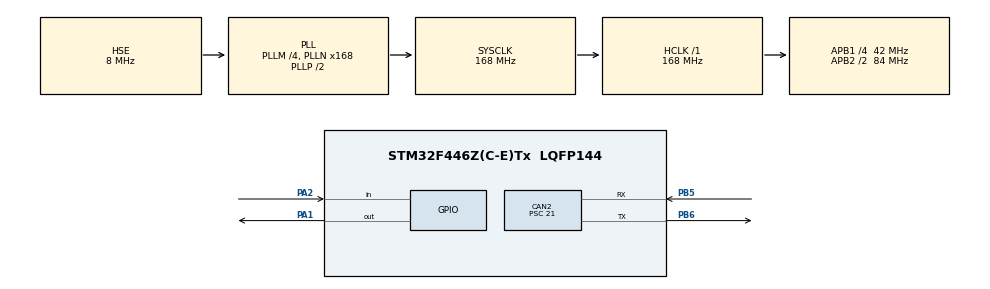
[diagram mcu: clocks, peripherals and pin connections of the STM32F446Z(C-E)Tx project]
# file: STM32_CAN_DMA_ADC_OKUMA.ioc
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CAN2.BS1=CAN_BS1_2TQ
CAN2.CalculateBaudRate=500000
CAN2.CalculateTimeBit=2000
CAN2.CalculateTimeQuantum=500.0
CAN2.Prescaler=21
Mcu.Family=STM32F4
Mcu.Name=STM32F446Z(C-E)Tx
Mcu.Package=LQFP144
NVIC.CAN2_RX0_IRQn=true\:0\:0\:false\:false\:true\:true\:true\:true
NVIC.PriorityGroup=NVIC_PRIORITYGROUP_4
PA1.Signal=GPIO_Output
PA2.Signal=GPIO_Input
PB5.Mode=CAN_Activate
PB5.Signal=CAN2_RX
PB6.Mode=CAN_Activate
PB6.Signal=CAN2_TX
PH0-OSC_IN.Mode=HSE-External-Oscillator
PH0-OSC_IN.Signal=RCC_OSC_IN
PH1-OSC_OUT.Mode=HSE-External-Oscillator
PH1-OSC_OUT.Signal=RCC_OSC_OUT
ProjectManager.HeapSize=0x200
ProjectManager.StackSize=0x400
ProjectManager.TargetToolchain=STM32CubeIDE
RCC.AHBFreq_Value=168000000
RCC.APB1CLKDivider=RCC_HCLK_DIV4
RCC.APB1Freq_Value=42000000
RCC.APB1TimFreq_Value=84000000
RCC.APB2CLKDivider=RCC_HCLK_DIV2
RCC.APB2Freq_Value=84000000
RCC.APB2TimFreq_Value=168000000
RCC.CortexFreq_Value=168000000
RCC.HCLKFreq_Value=168000000
RCC.HSE_VALUE=8000000
RCC.PLLM=4
RCC.PLLN=168
RCC.PLLSourceVirtual=RCC_PLLSOURCE_HSE
RCC.SYSCLKFreq_VALUE=168000000
RCC.SYSCLKSource=RCC_SYSCLKSOURCE_PLLCLK
RCC.USBFreq_Value=168000000
RCC.VCOOutputFreq_Value=336000000
board=custom

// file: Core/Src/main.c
/* USER CODE BEGIN Header */
/**
  ******************************************************************************
  * @file           : main.c
  * @brief          : Main program body
  ******************************************************************************
  * @attention
  *
  * Copyright (c) 2024 STMicroelectronics.
  * All rights reserved.
  *
  * This software is licensed under terms that can be found in the LICENSE file
  * in the root directory of this software component.
  * If no LICENSE file comes with this software, it is provided AS-IS.
  *
  ******************************************************************************
  */
/* USER CODE END Header */
#include "main.h"

CAN_HandleTypeDef hcan2;

/* USER CODE BEGIN PV */
uint8_t adc_value;

/* USER CODE END PV */

void SystemClock_Config(void);
static void MX_GPIO_Init(void);
static void MX_CAN2_Init(void);

int main(void)
{

  /* MCU Configuration--------------------------------------------------------*/

  /* Reset of all peripherals, Initializes the Flash interface and the Systick. */
  HAL_Init();

  /* Configure the system clock */
  SystemClock_Config();

  /* Initialize all configured peripherals */
  MX_GPIO_Init();
  MX_CAN2_Init();
  /* USER CODE BEGIN 2 */

  HAL_CAN_Start(&hcan2);
  HAL_ADC_Start_DMA(&hadc1, &adc_value, 1);

  /* USER CODE END 2 */

  /* Infinite loop */
  while (1)
  {

  }
}

void SystemClock_Config(void)
{
  RCC_OscInitTypeDef RCC_OscInitStruct = {0};
  RCC_ClkInitTypeDef RCC_ClkInitStruct = {0};

  /** Configure the main internal regulator output voltage
  */
  __HAL_RCC_PWR_CLK_ENABLE();
  __HAL_PWR_VOLTAGESCALING_CONFIG(PWR_REGULATOR_VOLTAGE_SCALE1);

  /** Initializes the RCC Oscillators according to the specified parameters
  * in the RCC_OscInitTypeDef structure.
  */
  RCC_OscInitStruct.OscillatorType = RCC_OSCILLATORTYPE_HSE;
  RCC_OscInitStruct.HSEState = RCC_HSE_ON;
  RCC_OscInitStruct.PLL.PLLState = RCC_PLL_ON;
  RCC_OscInitStruct.PLL.PLLSource = RCC_PLLSOURCE_HSE;
  RCC_OscInitStruct.PLL.PLLM = 4;
  RCC_OscInitStruct.PLL.PLLN = 168;
  RCC_OscInitStruct.PLL.PLLP = RCC_PLLP_DIV2;
  RCC_OscInitStruct.PLL.PLLQ = 2;
  RCC_OscInitStruct.PLL.PLLR = 2;
  if (HAL_RCC_OscConfig(&RCC_OscInitStruct) != HAL_OK)
  {
    Error_Handler();
  }

  /** Initializes the CPU, AHB and APB buses clocks
  */
  RCC_ClkInitStruct.ClockType = RCC_CLOCKTYPE_HCLK|RCC_CLOCKTYPE_SYSCLK
                              |RCC_CLOCKTYPE_PCLK1|RCC_CLOCKTYPE_PCLK2;
  RCC_ClkInitStruct.SYSCLKSource = RCC_SYSCLKSOURCE_PLLCLK;
  RCC_ClkInitStruct.AHBCLKDivider = RCC_SYSCLK_DIV1;
  RCC_ClkInitStruct.APB1CLKDivider = RCC_HCLK_DIV4;
  RCC_ClkInitStruct.APB2CLKDivider = RCC_HCLK_DIV2;

  if (HAL_RCC_ClockConfig(&RCC_ClkInitStruct, FLASH_LATENCY_5) != HAL_OK)
  {
    Error_Handler();
  }
}

static void MX_CAN2_Init(void)
{

  hcan2.Instance = CAN2;
  hcan2.Init.Prescaler = 21;
  hcan2.Init.Mode = CAN_MODE_NORMAL;
  hcan2.Init.SyncJumpWidth = CAN_SJW_1TQ;
  hcan2.Init.TimeSeg1 = CAN_BS1_2TQ;
  hcan2.Init.TimeSeg2 = CAN_BS2_1TQ;
  hcan2.Init.TimeTriggeredMode = DISABLE;
  hcan2.Init.AutoBusOff = DISABLE;
  hcan2.Init.AutoWakeUp = DISABLE;
  hcan2.Init.AutoRetransmission = DISABLE;
  hcan2.Init.ReceiveFifoLocked = DISABLE;
  hcan2.Init.TransmitFifoPriority = DISABLE;
  if (HAL_CAN_Init(&hcan2) != HAL_OK)
  {
    Error_Handler();
  }

}

static void MX_GPIO_Init(void)
{
  GPIO_InitTypeDef GPIO_InitStruct = {0};

  /* GPIO Ports Clock Enable */
  __HAL_RCC_GPIOH_CLK_ENABLE();
  __HAL_RCC_GPIOA_CLK_ENABLE();
  __HAL_RCC_GPIOB_CLK_ENABLE();

  /*Configure GPIO pin Output Level */
  HAL_GPIO_WritePin(GPIOA, GPIO_PIN_1, GPIO_PIN_RESET);

  /*Configure GPIO pin : PA1 */
  GPIO_InitStruct.Pin = GPIO_PIN_1;
  GPIO_InitStruct.Mode = GPIO_MODE_OUTPUT_PP;
  GPIO_InitStruct.Pull = GPIO_NOPULL;
  GPIO_InitStruct.Speed = GPIO_SPEED_FREQ_LOW;
  HAL_GPIO_Init(GPIOA, &GPIO_InitStruct);

  /*Configure GPIO pin : PA2 */
  GPIO_InitStruct.Pin = GPIO_PIN_2;
  GPIO_InitStruct.Mode = GPIO_MODE_INPUT;
  GPIO_InitStruct.Pull = GPIO_NOPULL;
  HAL_GPIO_Init(GPIOA, &GPIO_InitStruct);

}

void Error_Handler(void)
{
  __disable_irq();
  while (1)
  {
  }
}
